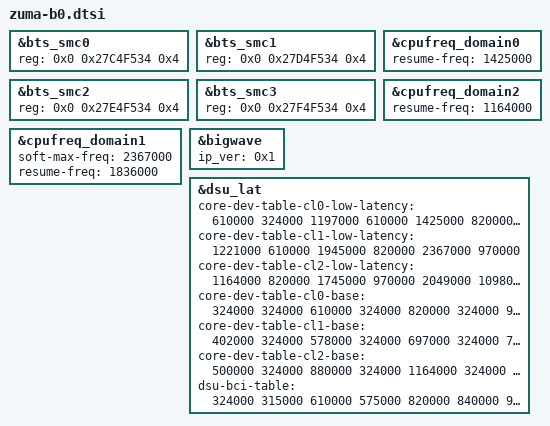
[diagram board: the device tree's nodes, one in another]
// SPDX-License-Identifier: GPL-2.0-only
/*
 * Copyright 2021 Google LLC.
 *
 */

#include "zuma.dtsi"

&bts_smc0 {
	reg = <0x0 0x27C4F534 0x4>;
};

&bts_smc1 {
	reg = <0x0 0x27D4F534 0x4>;
};

&bts_smc2 {
	reg = <0x0 0x27E4F534 0x4>;
};

&bts_smc3 {
	reg = <0x0 0x27F4F534 0x4>;
};

&cpufreq_domain0 {
	resume-freq = <1425000>;
};

&cpufreq_domain1 {
	soft-max-freq = <2367000>;
	resume-freq = <1836000>;
};

&cpufreq_domain2 {
	resume-freq = <1164000>;
};

&bigwave {
	ip_ver = <0x1>;
};

&dsu_lat {
		/* CL0         DSU */
	core-dev-table-cl0-low-latency =
		<  610000        324000
		  1197000        610000
		  1425000        820000
		  1785000        970000
		  2024000       1197000
		  2147000       1548000 >;

		/* CL1         DSU */
	core-dev-table-cl1-low-latency =
		< 1221000       610000
		  1945000       820000
		  2367000       970000 >;

		/* CL2         DSU */
	core-dev-table-cl2-low-latency =
		< 1164000       820000
		  1745000       970000
		  2049000      1098000
		  2556000      1197000
		  2802000      1328000 >;

		   /* CL0         DSU */
	core-dev-table-cl0-base =
		<  324000        324000
		   610000        324000
		   820000        324000
		   955000        324000
		  1098000        610000
		  1197000        610000
		  1328000        610000
		  1425000        610000
		  1548000        610000
		  1704000        610000 >;

		   /* CL1         DSU */
	core-dev-table-cl1-base =
		<  402000       324000
		   578000       324000
		   697000       324000
		   712000       324000
		   910000       324000
		  1065000       324000
		  1221000       324000
		  1328000       324000
		  1418000       610000
		  1572000       610000
		  1836000       610000
		  1945000       610000
		  2130000       610000
		  2245000       610000
		  2367000       820000 >;

		   /* CL2         DSU */
	core-dev-table-cl2-base =
		<  500000       324000
		   880000       324000
		  1164000       324000
		  1298000       610000
		  1557000       610000
		  1745000       610000
		  1885000       610000
		  2049000       610000
		  2147000       610000
		  2294000       610000
		  2363000       610000
		  2556000       820000
		  2687000       820000
		  2802000       820000
		  2914000       820000
		  2943000       820000>;

	dsu-bci-table =
		/* DSU         BCI */
		< 324000        315000
		610000        575000
		820000        840000
		970000        1050000
		1098000       1050000
		1197000       1205000
		1328000       1205000
		1444000       1205000
		1548000       1401000
		1800000       1401000
		1880000       1401000
		1950000       1401000
		2024000       1401000
		2120000       1401000>;
};
